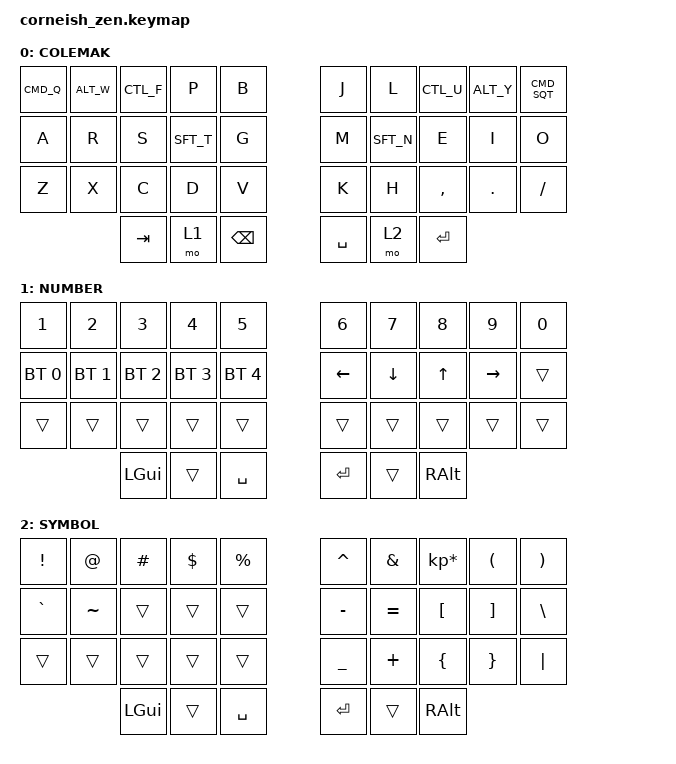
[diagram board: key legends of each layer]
#include <behaviors.dtsi>
#include <dt-bindings/zmk/keys.h>
#include <dt-bindings/zmk/bt.h>

/ {
  chosen {
    zmk,matrix_transform = &default_transform;
    //zmk,matrix_transform = &five_column_transform;
  };
};

/ {
        keymap {
                compatible = "zmk,keymap";

                default_layer {
                        label = "COLEMAK";
// -----------------------------------------------------------------------------------------
// |  Q  |  W  |  F  |  P  |  B  |   |  J  |  L   |  U  |  Y  |  '  |
// |  A  |  R  |  S  |  T  |  G  |   |  M  |  N   |  E  |  I  |  O  |
// |  Z  |  X  |  C  |  D  |  V  |   |  K  |  H   |  ,  |  .  |  /  |
//             | GUI | LWR | BSP |   | SPC | RSE  | ENT |
                        bindings = <
   CMD_Q ALT_W CTL_F &kp P &kp B   &kp J &kp L  CTL_U     ALT_Y   CMD_SQT
   &kp A &kp R &kp S SFT_T &kp G   &kp M SFT_N  &kp E     &kp I   &kp O
   &kp Z &kp X &kp C &kp D &kp V   &kp K &kp H  &kp COMMA &kp DOT &kp FSLH
         &kp TAB &mo 1 &kp BSPC   &kp SPACE &mo 2 &kp RET
                        >;
                };
                lower_layer {
                        label = "NUMBER";
// -----------------------------------------------------------------------------------------
// |  1  |  2  |  3  |  4  |  5  |   |  6  |  7  |  8  |  9  |  0  |
// | BT1 | BT2 | BT3 | BT4 | BT5 |   | LFT | DWN |  UP | RGT |     |
// |     |     |     |     |     |   |     |     |     |     |     | 
//             | GUI |     | SPC |   | ENT |     | ALT |
                        bindings = <
   &kp N1       &kp N2       &kp N3       &kp N4       &kp N5         &kp N6   &kp N7   &kp N8 &kp N9    &kp N0
   &bt BT_SEL 0 &bt BT_SEL 1 &bt BT_SEL 2 &bt BT_SEL 3 &bt BT_SEL 4   &kp LEFT &kp DOWN &kp UP &kp RIGHT &trans
   &trans       &trans       &trans       &trans       &trans         &trans   &trans   &trans &trans    &trans
                          	 &kp LGUI     &trans       &kp SPACE      &kp RET  &trans   &kp RALT
                        >;
                };

                raise_layer {
                        label = "SYMBOL";
// -----------------------------------------------------------------------------------------
// |  !  |  @  |  #  |  $  |  %  |   |  ^  |  &  |  *  |  (  |  )  |
// |  `  |  ~  |     |     |     |   |  -  |  =  |  [  |  ]  |  \  |
// |     |     |     |     |     |   |  _  |  +  |  {  |  }  | "|" |
//             | GUI |     | SPC |   | ENT |     | ALT |
                        bindings = <
   &kp EXCL  &kp AT    &kp HASH &kp DLLR &kp PRCNT   &kp CARET &kp AMPS  &kp KP_MULTIPLY &kp LPAR &kp RPAR
   &kp GRAVE &kp TILDE &trans   &trans   &trans      &kp MINUS &kp EQUAL &kp LBKT        &kp RBKT &kp BSLH
   &trans    &trans    &trans   &trans   &trans      &kp UNDER &kp PLUS  &kp LBRC        &kp RBRC &kp PIPE
                       &kp LGUI &trans   &kp SPACE   &kp RET   &trans    &kp RALT
                        >;
                };
        };
};
